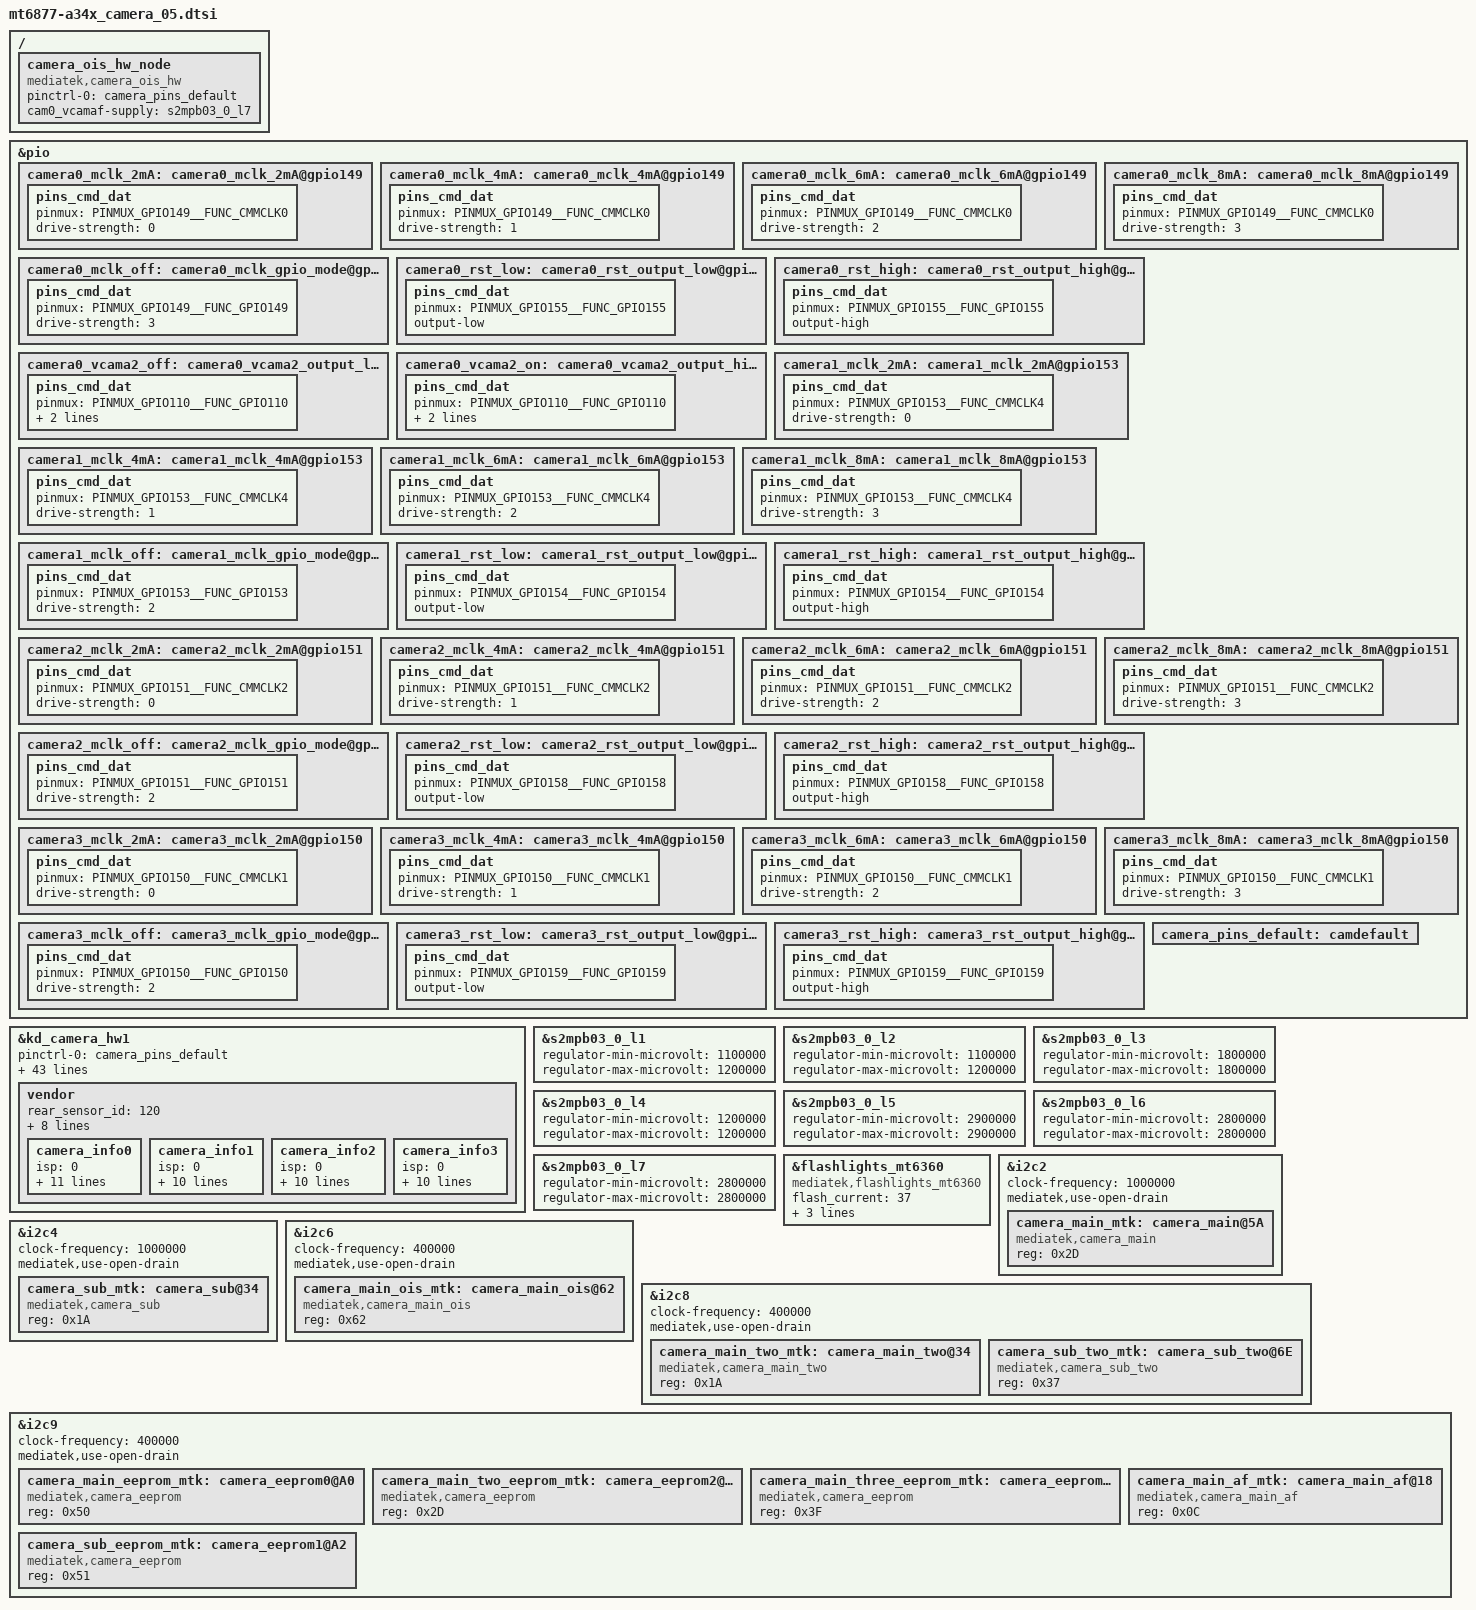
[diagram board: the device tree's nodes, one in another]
/*
 * Copyright (c) 2021 MediaTek Inc.
 *
 * This program is free software; you can redistribute it and/or modify
 * it under the terms of the GNU General Public License version 2 as
 * published by the Free Software Foundation.
 *
 * This program is distributed in the hope that it will be useful,
 * but WITHOUT ANY WARRANTY; without even the implied warranty of
 * MERCHANTABILITY or FITNESS FOR A PARTICULAR PURPOSE.  See the
 * GNU General Public License for more details.
 */

/******** A34-5G Board  ***********
 *    SW          :   HW   : Sensor
 * camera0(Wide)  : RCAM1  : IMX582
 * camera1(Front) : FCAM   : IMX258 HI1339
 * camera2(UW)    : RCAM2  : S5K4HA SR846D
 * camera4(Macro) : RCAM3  : GC5035
 ***********************************/

/* CAMERA GPIO standardization */
&pio {
	/****************  camera0  ***************/
	// MCLK
	camera0_mclk_2mA: camera0_mclk_2mA@gpio149 {
		pins_cmd_dat {
			pinmux = <PINMUX_GPIO149__FUNC_CMMCLK0>;
			drive-strength = <0>;
		};
	};
	camera0_mclk_4mA: camera0_mclk_4mA@gpio149 {
		pins_cmd_dat {
			pinmux = <PINMUX_GPIO149__FUNC_CMMCLK0>;
			drive-strength = <1>;
		};
	};
	camera0_mclk_6mA: camera0_mclk_6mA@gpio149 {
		pins_cmd_dat {
			pinmux = <PINMUX_GPIO149__FUNC_CMMCLK0>;
			drive-strength = <2>;
		};
	};
	camera0_mclk_8mA: camera0_mclk_8mA@gpio149 {
		pins_cmd_dat {
			pinmux = <PINMUX_GPIO149__FUNC_CMMCLK0>;
			drive-strength = <3>;
		};
	};
	camera0_mclk_off: camera0_mclk_gpio_mode@gpio149 {
		pins_cmd_dat {
			pinmux = <PINMUX_GPIO149__FUNC_GPIO149>;
			drive-strength = <3>;
		};
	};

	// Reset
	camera0_rst_low: camera0_rst_output_low@gpio155 {
		pins_cmd_dat {
			pinmux = <PINMUX_GPIO155__FUNC_GPIO155>;
			output-low;
		};
	};
	camera0_rst_high: camera0_rst_output_high@gpio155 {
		pins_cmd_dat {
			pinmux = <PINMUX_GPIO155__FUNC_GPIO155>;
			output-high;
		};
	};

	// AVDD2
	camera0_vcama2_off: camera0_vcama2_output_low@gpio110 {
		pins_cmd_dat {
			pinmux = <PINMUX_GPIO110__FUNC_GPIO110>;
			slew-rate = <1>;
			output-low;
		};
	};
	camera0_vcama2_on: camera0_vcama2_output_high@gpio110 {
		pins_cmd_dat {
			pinmux = <PINMUX_GPIO110__FUNC_GPIO110>;
			slew-rate = <1>;
			output-high;
		};
	};

	// DVDD
	// GPIO contol is not required

	// I2C setting for status of power off is not used

	/****************  camera1  ***************/
	// MCLK
	camera1_mclk_2mA: camera1_mclk_2mA@gpio153 {
		pins_cmd_dat {
			pinmux = <PINMUX_GPIO153__FUNC_CMMCLK4>;
			drive-strength = <0>;
		};
	};
	camera1_mclk_4mA: camera1_mclk_4mA@gpio153 {
		pins_cmd_dat {
			pinmux = <PINMUX_GPIO153__FUNC_CMMCLK4>;
			drive-strength = <1>;
		};
	};
	camera1_mclk_6mA: camera1_mclk_6mA@gpio153 {
		pins_cmd_dat {
			pinmux = <PINMUX_GPIO153__FUNC_CMMCLK4>;
			drive-strength = <2>;
		};
	};
	camera1_mclk_8mA: camera1_mclk_8mA@gpio153 {
		pins_cmd_dat {
			pinmux = <PINMUX_GPIO153__FUNC_CMMCLK4>;
			drive-strength = <3>;
		};
	};
	camera1_mclk_off: camera1_mclk_gpio_mode@gpio153 {
		pins_cmd_dat {
			pinmux = <PINMUX_GPIO153__FUNC_GPIO153>;
			drive-strength = <2>;
		};
	};

	// Reset
	camera1_rst_low: camera1_rst_output_low@gpio154 {
		pins_cmd_dat {
			pinmux = <PINMUX_GPIO154__FUNC_GPIO154>;
			output-low;
		};
	};
	camera1_rst_high: camera1_rst_output_high@gpio154 {
		pins_cmd_dat {
			pinmux = <PINMUX_GPIO154__FUNC_GPIO154>;
			output-high;
		};
	};

	// AVDD
	// GPIO contol is not required

	// DVDD
	// GPIO contol is not required

	// I2C setting for status of power off is not used

	/****************  camera2  ***************/
	// MCLK
	camera2_mclk_2mA: camera2_mclk_2mA@gpio151 {
		pins_cmd_dat {
			pinmux = <PINMUX_GPIO151__FUNC_CMMCLK2>;
			drive-strength = <0>;
		};
	};
	camera2_mclk_4mA: camera2_mclk_4mA@gpio151 {
		pins_cmd_dat {
			pinmux = <PINMUX_GPIO151__FUNC_CMMCLK2>;
			drive-strength = <1>;
		};
	};
	camera2_mclk_6mA: camera2_mclk_6mA@gpio151 {
		pins_cmd_dat {
			pinmux = <PINMUX_GPIO151__FUNC_CMMCLK2>;
			drive-strength = <2>;
		};
	};
	camera2_mclk_8mA: camera2_mclk_8mA@gpio151 {
		pins_cmd_dat {
			pinmux = <PINMUX_GPIO151__FUNC_CMMCLK2>;
			drive-strength = <3>;
		};
	};
	camera2_mclk_off: camera2_mclk_gpio_mode@gpio151 {
		pins_cmd_dat {
			pinmux = <PINMUX_GPIO151__FUNC_GPIO151>;
			drive-strength = <2>;
		};
	};

	// Reset
	camera2_rst_low: camera2_rst_output_low@gpio158 {
		pins_cmd_dat {
			pinmux = <PINMUX_GPIO158__FUNC_GPIO158>;
			output-low;
		};
	};
	camera2_rst_high: camera2_rst_output_high@gpio158 {
		pins_cmd_dat {
			pinmux = <PINMUX_GPIO158__FUNC_GPIO158>;
			output-high;
		};
	};

	// AVDD setting is not used
	// GPIO contol is not required

	// DVDD
	// GPIO contol is not required

	// I2C setting for status of power off is not used

	/****************  camera3  ***************/
	// MCLK
	camera3_mclk_2mA: camera3_mclk_2mA@gpio150 {
		pins_cmd_dat {
			pinmux = <PINMUX_GPIO150__FUNC_CMMCLK1>;
			drive-strength = <0>;
		};
	};
	camera3_mclk_4mA: camera3_mclk_4mA@gpio150 {
		pins_cmd_dat {
			pinmux = <PINMUX_GPIO150__FUNC_CMMCLK1>;
			drive-strength = <1>;
		};
	};
	camera3_mclk_6mA: camera3_mclk_6mA@gpio150 {
		pins_cmd_dat {
			pinmux = <PINMUX_GPIO150__FUNC_CMMCLK1>;
			drive-strength = <2>;
		};
	};
	camera3_mclk_8mA: camera3_mclk_8mA@gpio150 {
		pins_cmd_dat {
			pinmux = <PINMUX_GPIO150__FUNC_CMMCLK1>;
			drive-strength = <3>;
		};
	};
	camera3_mclk_off: camera3_mclk_gpio_mode@gpio150 {
		pins_cmd_dat {
			pinmux = <PINMUX_GPIO150__FUNC_GPIO150>;
			drive-strength = <2>;
		};
	};

	// Reset
	camera3_rst_low: camera3_rst_output_low@gpio159 {
		pins_cmd_dat {
			pinmux = <PINMUX_GPIO159__FUNC_GPIO159>;
			output-low;
		};
	};
	camera3_rst_high: camera3_rst_output_high@gpio159 {
		pins_cmd_dat {
			pinmux = <PINMUX_GPIO159__FUNC_GPIO159>;
			output-high;
		};
	};

	// AVDD
	// GPIO contol is not required

	// DVDD
	// GPIO contol is not required

	// I2C setting for status of power off is not used

	/****************  default  ***************/
	camera_pins_default: camdefault {
	};
};

&kd_camera_hw1 {
	pinctrl-names = "default",
		"cam0_rst0", "cam0_rst1",
		"cam0_ldo_vcama2_0", "cam0_ldo_vcama2_1",
		"cam0_mclk_off",
		"cam0_mclk_2mA", "cam0_mclk_4mA",
		"cam0_mclk_6mA", "cam0_mclk_8mA",

		"cam1_rst0", "cam1_rst1",
		"cam1_mclk_off",
		"cam1_mclk_2mA", "cam1_mclk_4mA",
		"cam1_mclk_6mA", "cam1_mclk_8mA",

		"cam2_rst0", "cam2_rst1",
		"cam2_mclk_off",
		"cam2_mclk_2mA", "cam2_mclk_4mA",
		"cam2_mclk_6mA", "cam2_mclk_8mA",

		"cam3_rst0", "cam3_rst1",
		"cam3_mclk_off",
		"cam3_mclk_2mA", "cam3_mclk_4mA",
		"cam3_mclk_6mA", "cam3_mclk_8mA";

	pinctrl-0 = <&camera_pins_default>;
	pinctrl-1 = <&camera0_rst_low>;
	pinctrl-2 = <&camera0_rst_high>;
	pinctrl-3 = <&camera0_vcama2_off>;
	pinctrl-4 = <&camera0_vcama2_on>;
	pinctrl-5 = <&camera0_mclk_off>;
	pinctrl-6 = <&camera0_mclk_2mA>;
	pinctrl-7 = <&camera0_mclk_4mA>;
	pinctrl-8 = <&camera0_mclk_6mA>;
	pinctrl-9 = <&camera0_mclk_8mA>;

	pinctrl-10 = <&camera1_rst_low>;
	pinctrl-11 = <&camera1_rst_high>;
	pinctrl-12 = <&camera1_mclk_off>;
	pinctrl-13 = <&camera1_mclk_2mA>;
	pinctrl-14 = <&camera1_mclk_4mA>;
	pinctrl-15 = <&camera1_mclk_6mA>;
	pinctrl-16 = <&camera1_mclk_8mA>;

	pinctrl-17 = <&camera2_rst_low>;
	pinctrl-18 = <&camera2_rst_high>;
	pinctrl-19 = <&camera2_mclk_off>;
	pinctrl-20 = <&camera2_mclk_2mA>;
	pinctrl-21 = <&camera2_mclk_4mA>;
	pinctrl-22 = <&camera2_mclk_6mA>;
	pinctrl-23 = <&camera2_mclk_8mA>;

	pinctrl-24 = <&camera3_rst_low>;
	pinctrl-25 = <&camera3_rst_high>;
	pinctrl-26 = <&camera3_mclk_off>;
	pinctrl-27 = <&camera3_mclk_2mA>;
	pinctrl-28 = <&camera3_mclk_4mA>;
	pinctrl-29 = <&camera3_mclk_6mA>;
	pinctrl-30 = <&camera3_mclk_8mA>;

	/********* Regulator setting **************/
	// camera0
	cam0_vcama-supply = <&s2mpb03_0_l5>;
	cam0_vcamd-supply = <&s2mpb03_0_l2>;
	cam0_vcamio-supply = <&s2mpb03_0_l3>;
	cam0_vcamaf-supply = <&s2mpb03_0_l7>;

	// camera1
	cam1_vcama-supply = <&s2mpb03_0_l6>;
	cam1_vcamd-supply = <&s2mpb03_0_l1>;
	cam1_vcamio-supply = <&s2mpb03_0_l3>;

	// camera2
	cam2_vcama-supply = <&s2mpb03_0_l6>;
	cam2_vcamd-supply = <&s2mpb03_0_l4>;
	cam2_vcamio-supply = <&s2mpb03_0_l3>;

	// camera3
	cam3_vcama-supply = <&s2mpb03_0_l6>;
	cam3_vcamd-supply = <&s2mpb03_0_l4>;
	cam3_vcamio-supply = <&s2mpb03_0_l3>;

	status = "okay";
	vendor {
		rear_sensor_id = <120>;   /* SENSOR_NAME_IMX582 */
		front_sensor_id = <121>;  /* SENSOR_NAME_IMX258 */
		rear2_sensor_id = <210>;  /* SENSOR_NAME_S5K4HAYX */
		rear3_sensor_id = <210>;  /* SENSOR_NAME_GC5035 */

		use_dualcam_set_cal;
		use_module_check;
		//skip_cal_loading;       /* for test without cal loading */
		//check_final_cam_module; /* use after DVR */
		max_supported_camera = <4>;
		supported_cameraId = <0 1 50 54>; /* REAR, FRONT, REAR2, REAR3 */

		max_camera_num = <5>;
		camera_info0 {             /* 0 : rear - IMX582 */
			isp = <0>;             /* 0 : INT , 1 : EXT , 2 : SOC */
			cal_memory = <2>;      /* 0 : N , 1 : FROM , 2 : EEPROM , 3 : OTP  */
			read_version = <0>;    /* 0 : SYSFS , 1 : CAMON */
			core_voltage = <0>;    /* 0 : N , 1 : Y  */
			upgrade = <0>;         /* 0 : N , 1 : SYSFS , 2 : CAMON */
			companion = <0>;       /* 0 : N , 1 : Y  */
			ois = <1>;             /* 0 : N , 1 : Y  */
			valid = <1>;           /* 0 : INVALID, 1 : VALID */
			dual_open = <0>;       /* 0 : SINGLE_OPEN , 1 : DUAL_OPEN */
			position = <0>;        /* 0 : Rear, 1:Front, 2:Rear2, 3:Front2, 4:Rear3, 6:Rear4 */
			//includes_sub = <4>;  /* include this for common eeprom. <_position_> - position of the sub camera */
			afcal_type=<20>;       /* output format - 1: Near, Middle..., Far , 20: Near, Far, Middle... */
			use_adaptive_mipi=<0>; /* 0 : N, 1 : Y */
		};
		camera_info1 {             /* 1 : front - IMX258 */
			isp = <0>;             /* 0 : INT , 1 : EXT , 2 : SOC */
			cal_memory = <2>;      /* 0 : N , 1 : FROM , 2 : EEPROM , 3 : OTP  */
			read_version = <0>;    /* 0 : SYSFS , 1 : CAMON */
			core_voltage = <0>;    /* 0 : N , 1 : Y  */
			upgrade = <0>;         /* 0 : N , 1 : SYSFS , 2 : CAMON */
			companion = <0>;       /* 0 : N , 1 : Y  */
			ois = <0>;             /* 0 : N , 1 : Y  */
			valid = <1>;           /* 0 : INVALID, 1 : VALID */
			dual_open = <0>;       /* 0 : SINGLE_OPEN , 1 : DUAL_OPEN */
			position = <1>;        /* 0 : Rear, 1:Front, 2:Rear2, 3:Front2, 4:Rear3, 6:Rear4 */
			use_adaptive_mipi=<1>; /* 0 : N, 1 : Y */
		};
		camera_info2 {             /* 3 : rear2 - S4K4HAYX */
			isp = <0>;             /* 0 : INT , 1 : EXT , 2 : SOC */
			cal_memory = <3>;      /* 0 : N , 1 : FROM , 2 : EEPROM , 3 : OTP  */
			read_version = <0>;    /* 0 : SYSFS , 1 : CAMON */
			core_voltage = <0>;    /* 0 : N , 1 : Y  */
			upgrade = <0>;         /* 0 : N , 1 : SYSFS , 2 : CAMON */
			companion = <0>;       /* 0 : N , 1 : Y  */
			ois = <0>;             /* 0 : N , 1 : Y  */
			valid = <1>;           /* 0 : INVALID, 1 : VALID */
			dual_open = <0>;       /* 0 : SINGLE_OPEN , 1 : DUAL_OPEN */
			position = <2>;        /* 0 : Rear, 1:Front, 2:Rear2, 3:Front2, 4:Rear3, 6:Rear4 */
			use_adaptive_mipi=<0>; /* 0 : N, 1 : Y */
		};
		camera_info3 {             /* 4 : rear3 - GC5035 */
			isp = <0>;             /* 0 : INT , 1 : EXT , 2 : SOC */
			cal_memory = <3>;      /* 0 : N , 1 : FROM , 2 : EEPROM , 3 : OTP  */
			read_version = <0>;    /* 0 : SYSFS , 1 : CAMON */
			core_voltage = <0>;    /* 0 : N , 1 : Y  */
			upgrade = <0>;         /* 0 : N , 1 : SYSFS , 2 : CAMON */
			companion = <0>;       /* 0 : N , 1 : Y  */
			ois = <0>;             /* 0 : N , 1 : Y  */
			valid = <1>;           /* 0 : INVALID, 1 : VALID */
			dual_open = <0>;       /* 0 : SINGLE_OPEN , 1 : DUAL_OPEN */
			position = <4>;        /* 0 : Rear, 1:Front, 2:Rear2, 3:Front2, 4:Rear3, 6:Rear4 */
			use_adaptive_mipi=<0>; /* 0 : N, 1 : Y */
		};
	};
};
/* CAMERA GPIO end */

/* CAMERA OIS */
/ {
	fragment@cam_ois_drv {
		target-path = "/";
		__overlay__ {

			camera_ois_hw_node: camera_ois_hw_node {
				compatible = "mediatek,camera_ois_hw";
				pinctrl-names = "default";

				pinctrl-0 = <&camera_pins_default>;
				cam0_vcamaf-supply = <&s2mpb03_0_l7>;

				status = "okay";
			};
		};
	};
};
/* CAMERA OIS end */

/* CAM PMIC */
&s2mpb03_0_l1 {
	regulator-min-microvolt = <1100000>;
	regulator-max-microvolt = <1200000>;
};

&s2mpb03_0_l2 {
	regulator-min-microvolt = <1100000>;
	regulator-max-microvolt = <1200000>;
};

&s2mpb03_0_l3 {
	regulator-min-microvolt = <1800000>;
	regulator-max-microvolt = <1800000>;
};

&s2mpb03_0_l4 {
	regulator-min-microvolt = <1200000>;
	regulator-max-microvolt = <1200000>;
};

&s2mpb03_0_l5 {
	regulator-min-microvolt = <2900000>;
	regulator-max-microvolt = <2900000>;
};

&s2mpb03_0_l6 {
	regulator-min-microvolt = <2800000>;
	regulator-max-microvolt = <2800000>;
};

&s2mpb03_0_l7 {
	regulator-min-microvolt = <2800000>;
	regulator-max-microvolt = <2800000>;
};

/* Flash */
&flashlights_mt6360 {
	compatible = "mediatek,flashlights_mt6360";
	flash_current = <37>;
	torch_current = <7>;
	factory_current = <15>;
	flashlight_current = <1 2 3 6 8>; /* 50, 75, 87.5, 175, 225 mA */
};

/*************************
*     Cmaera I2C
*************************/

&i2c2 {
	#address-cells = <1>;
	#size-cells = <0>;
	clock-frequency = <1000000>;
	mediatek,use-open-drain;
	camera_main_mtk:camera_main@5A {
		compatible = "mediatek,camera_main";
		reg = <0x2D>;
		status = "okay";
	};
};

&i2c4 {
	#address-cells = <1>;
	#size-cells = <0>;
	clock-frequency = <1000000>;
	mediatek,use-open-drain;
	camera_sub_mtk:camera_sub@34 {
		compatible = "mediatek,camera_sub";
		reg = <0x1A>;
		status = "okay";
	};
};

&i2c6 {
	#address-cells = <1>;
	#size-cells = <0>;
	clock-frequency = <400000>;
	mediatek,use-open-drain;
	camera_main_ois_mtk:camera_main_ois@62 {
		compatible = "mediatek,camera_main_ois";
		reg = <0x62>;
		status = "okay";
	};
};

&i2c8 {
	#address-cells = <1>;
	#size-cells = <0>;
	clock-frequency = <400000>;
	mediatek,use-open-drain;

	camera_main_two_mtk:camera_main_two@34 {
		compatible = "mediatek,camera_main_two";
		reg = <0x1A>;
		status = "okay";
	};

	camera_sub_two_mtk:camera_sub_two@6E {
		compatible = "mediatek,camera_sub_two";
		reg = <0x37>;
		status = "okay";
	};
};

&i2c9 {
	#address-cells = <1>;
	#size-cells = <0>;
	clock-frequency = <400000>;
	mediatek,use-open-drain;

	/* Rear camera */
	camera_main_eeprom_mtk:camera_eeprom0@A0 {
		compatible = "mediatek,camera_eeprom";
		reg = <0x50>;
		status = "okay";
	};

	camera_main_two_eeprom_mtk:camera_eeprom2@5A {
		compatible = "mediatek,camera_eeprom";
		reg = <0x2D>;
		status = "okay";
	};

	camera_main_three_eeprom_mtk:camera_eeprom3@7E {
		compatible = "mediatek,camera_eeprom";
		reg = <0x3F>;
		status = "okay";
	};

	camera_sub_eeprom_mtk:camera_eeprom1@A2 {
		compatible = "mediatek,camera_eeprom";
		reg = <0x51>;
		status = "okay";
	};

	camera_main_af_mtk:camera_main_af@18 {
		compatible = "mediatek,camera_main_af";
		reg = <0x0C>;
		status = "okay";
	};
};
